VERSION ""

NS_ :

BS_:

BU_: VCU BMS Dash Daq RMS_PM_Controller

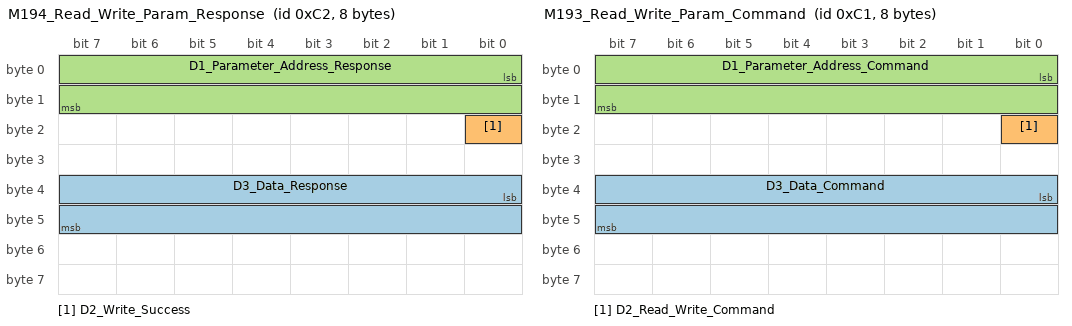
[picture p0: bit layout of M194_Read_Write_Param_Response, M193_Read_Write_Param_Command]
BO_ 194 M194_Read_Write_Param_Response: 8 RMS_PM_Controller
 SG_ D3_Data_Response : 32|16@1- (1,0) [-32768|32767] "" Vector__XXX
 SG_ D2_Write_Success : 16|1@1+ (1,0) [0|1] "" Vector__XXX
 SG_ D1_Parameter_Address_Response : 0|16@1+ (1,0) [0|65535] "" Vector__XXX

BO_ 193 M193_Read_Write_Param_Command: 8 RMS_PM_Controller
 SG_ D3_Data_Command : 32|16@1- (1,0) [-32768|32767] "" Vector__XXX
 SG_ D2_Read_Write_Command : 16|1@1+ (1,0) [0|1] "" Vector__XXX
 SG_ D1_Parameter_Address_Command : 0|16@1+ (1,0) [0|65535] "" Vector__XXX

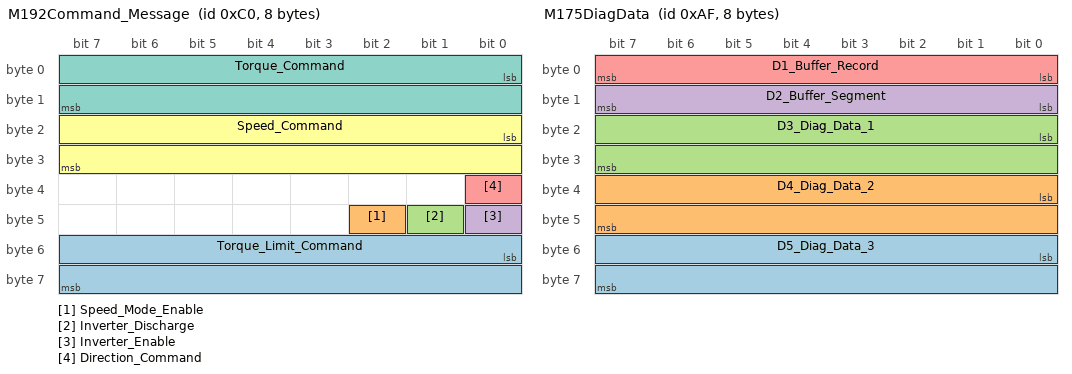
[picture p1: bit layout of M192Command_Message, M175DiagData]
BO_ 192 M192Command_Message: 8 RMS_PM_Controller
 SG_ Torque_Limit_Command : 48|16@1- (0.1,0) [-3276.8|3276.7] "" Vector__XXX
 SG_ Speed_Mode_Enable : 42|1@1+ (1,0) [0|1] "" Vector__XXX
 SG_ Inverter_Discharge : 41|1@1+ (1,0) [0|1] "" Vector__XXX
 SG_ Inverter_Enable : 40|1@1+ (1,0) [0|1] "" Vector__XXX
 SG_ Direction_Command : 32|1@1+ (1,0) [0|1] "" Vector__XXX
 SG_ Speed_Command : 16|16@1- (1,0) [-32768|32767] "" Vector__XXX
 SG_ Torque_Command : 0|16@1- (0.1,0) [-3276.8|3276.7] "" Vector__XXX

BO_ 175 M175DiagData: 8 RMS_PM_Controller
 SG_ D5_Diag_Data_3 : 48|16@1- (1,0) [-32768|32767] "" Vector__XXX
 SG_ D4_Diag_Data_2 : 32|16@1- (1,0) [-32768|32767] "" Vector__XXX
 SG_ D3_Diag_Data_1 : 16|16@1- (1,0) [-32768|32767] "" Vector__XXX
 SG_ D2_Buffer_Segment : 8|8@1+ (1,0) [0|5] "" Vector__XXX
 SG_ D1_Buffer_Record : 0|8@1+ (1,0) [0|255] "" Vector__XXX

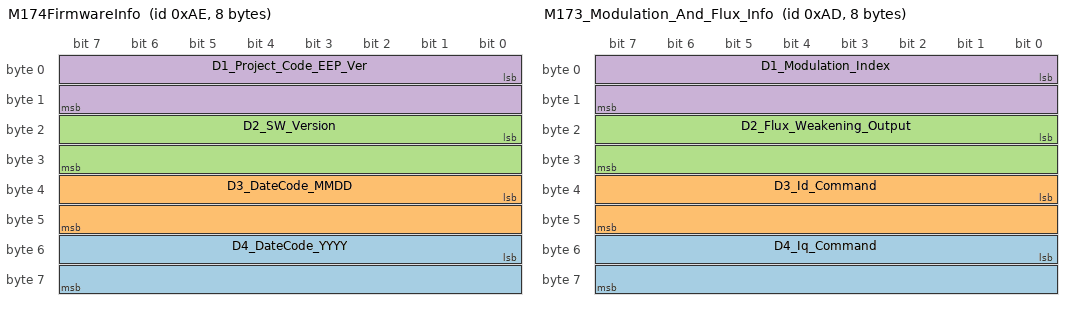
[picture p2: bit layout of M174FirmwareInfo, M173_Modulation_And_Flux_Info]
BO_ 174 M174FirmwareInfo: 8 RMS_PM_Controller
 SG_ D4_DateCode_YYYY : 48|16@1+ (1,0) [0|65535] "" Vector__XXX
 SG_ D3_DateCode_MMDD : 32|16@1+ (1,0) [0|65535] "" Vector__XXX
 SG_ D2_SW_Version : 16|16@1+ (1,0) [0|65535] "" Vector__XXX
 SG_ D1_Project_Code_EEP_Ver : 0|16@1+ (1,0) [0|65535] "" Vector__XXX

BO_ 173 M173_Modulation_And_Flux_Info: 8 RMS_PM_Controller
 SG_ D4_Iq_Command : 48|16@1- (0.1,0) [-3276.8|3276.7] "" Vector__XXX
 SG_ D3_Id_Command : 32|16@1- (0.1,0) [-3276.8|3276.7] "" Vector__XXX
 SG_ D2_Flux_Weakening_Output : 16|16@1- (0.1,0) [-3276.8|3276.7] "" Vector__XXX
 SG_ D1_Modulation_Index : 0|16@1- (0.0001,0) [-3.2768|3.2767] "" Vector__XXX

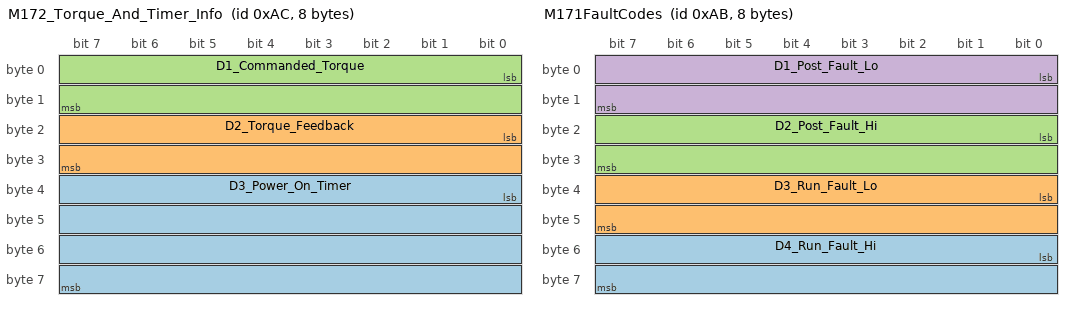
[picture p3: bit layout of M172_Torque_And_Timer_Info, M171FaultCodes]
BO_ 172 M172_Torque_And_Timer_Info: 8 RMS_PM_Controller
 SG_ D3_Power_On_Timer : 32|32@1+ (0.003,0) [0|12884800.0] "" Vector__XXX
 SG_ D2_Torque_Feedback : 16|16@1- (0.1,0) [-3276.8|3276.7] "" Vector__XXX
 SG_ D1_Commanded_Torque : 0|16@1- (0.1,0) [-3276.8|3276.7] "" Vector__XXX

BO_ 171 M171FaultCodes: 8 RMS_PM_Controller
 SG_ D4_Run_Fault_Hi : 48|16@1+ (1,0) [0|65535] "" Vector__XXX
 SG_ D3_Run_Fault_Lo : 32|16@1+ (1,0) [0|65535] "" Vector__XXX
 SG_ D2_Post_Fault_Hi : 16|16@1+ (1,0) [0|65535] "" Vector__XXX
 SG_ D1_Post_Fault_Lo : 0|16@1+ (1,0) [0|65535] "" Vector__XXX

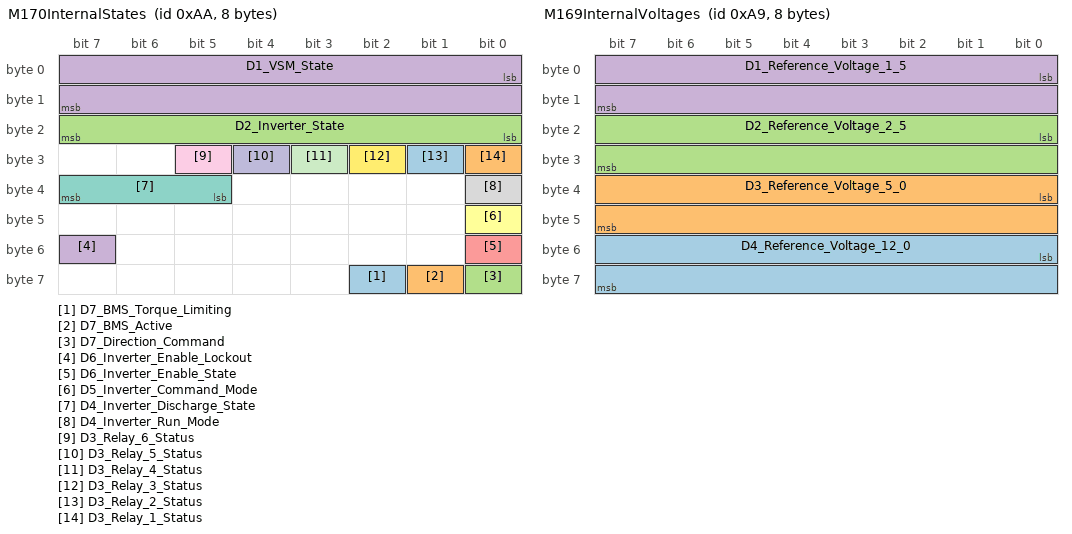
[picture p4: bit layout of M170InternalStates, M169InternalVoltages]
BO_ 170 M170InternalStates: 8 RMS_PM_Controller
 SG_ D7_BMS_Torque_Limiting : 58|1@1+ (1,0) [0|0] "" Vector__XXX
 SG_ D7_BMS_Active : 57|1@1+ (1,0) [0|1] "" Vector__XXX
 SG_ D7_Direction_Command : 56|1@1+ (1,0) [0|1] "" Vector__XXX
 SG_ D6_Inverter_Enable_Lockout : 55|1@1+ (1,0) [0|1] "" Vector__XXX
 SG_ D6_Inverter_Enable_State : 48|1@1+ (1,0) [0|1] "" Vector__XXX
 SG_ D5_Inverter_Command_Mode : 40|1@1+ (1,0) [0|1] "" Vector__XXX
 SG_ D4_Inverter_Discharge_State : 37|3@1+ (1,0) [0|7] "" Vector__XXX
 SG_ D4_Inverter_Run_Mode : 32|1@1+ (1,0) [0|1] "" Vector__XXX
 SG_ D3_Relay_6_Status : 29|1@1+ (1,0) [0|1] "" Vector__XXX
 SG_ D3_Relay_5_Status : 28|1@1+ (1,0) [0|1] "" Vector__XXX
 SG_ D3_Relay_4_Status : 27|1@1+ (1,0) [0|1] "" Vector__XXX
 SG_ D3_Relay_3_Status : 26|1@1+ (1,0) [0|1] "" Vector__XXX
 SG_ D3_Relay_2_Status : 25|1@1+ (1,0) [0|1] "" Vector__XXX
 SG_ D3_Relay_1_Status : 24|1@1+ (1,0) [0|1] "" Vector__XXX
 SG_ D2_Inverter_State : 16|8@1+ (1,0) [0|255] "" Vector__XXX
 SG_ D1_VSM_State : 0|16@1+ (1,0) [0|15] "" Vector__XXX

BO_ 169 M169InternalVoltages: 8 RMS_PM_Controller
 SG_ D4_Reference_Voltage_12_0 : 48|16@1- (0.01,0) [-327.68|327.67] "" Vector__XXX
 SG_ D3_Reference_Voltage_5_0 : 32|16@1- (0.01,0) [-327.68|327.67] "" Vector__XXX
 SG_ D2_Reference_Voltage_2_5 : 16|16@1- (0.01,0) [-327.68|327.67] "" Vector__XXX
 SG_ D1_Reference_Voltage_1_5 : 0|16@1- (0.01,0) [-327.68|327.67] "" Vector__XXX

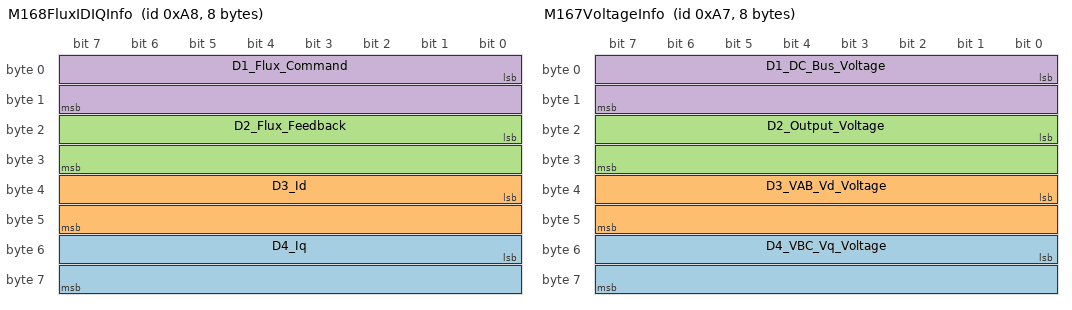
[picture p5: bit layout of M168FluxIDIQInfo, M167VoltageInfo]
BO_ 168 M168FluxIDIQInfo: 8 RMS_PM_Controller
 SG_ D4_Iq : 48|16@1- (0.1,0) [-3276.8|3276.7] "" Vector__XXX
 SG_ D3_Id : 32|16@1- (0.1,0) [-3276.8|3276.7] "" Vector__XXX
 SG_ D2_Flux_Feedback : 16|16@1- (0.001,0) [-32.768|32.767] "" Vector__XXX
 SG_ D1_Flux_Command : 0|16@1- (0.001,0) [-32.768|32.767] "" Vector__XXX

BO_ 167 M167VoltageInfo: 8 RMS_PM_Controller
 SG_ D4_VBC_Vq_Voltage : 48|16@1- (0.1,0) [-3276.8|3276.7] "" Vector__XXX
 SG_ D3_VAB_Vd_Voltage : 32|16@1- (0.1,0) [-3276.8|3276.7] "" Vector__XXX
 SG_ D2_Output_Voltage : 16|16@1- (0.1,0) [-3276.8|3276.7] "" Vector__XXX
 SG_ D1_DC_Bus_Voltage : 0|16@1- (0.1,0) [-3276.8|3276.7] "" Vector__XXX

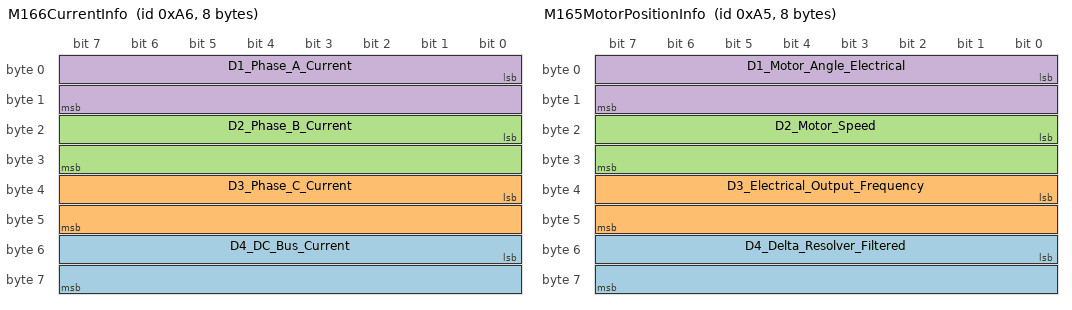
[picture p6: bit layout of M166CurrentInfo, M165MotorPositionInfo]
BO_ 166 M166CurrentInfo: 8 RMS_PM_Controller
 SG_ D4_DC_Bus_Current : 48|16@1- (0.1,0) [-3276.8|3276.7] "" Vector__XXX
 SG_ D3_Phase_C_Current : 32|16@1- (0.1,0) [-3276.8|3276.7] "" Vector__XXX
 SG_ D2_Phase_B_Current : 16|16@1- (0.1,0) [-3276.8|3276.7] "" Vector__XXX
 SG_ D1_Phase_A_Current : 0|16@1- (0.1,0) [-3276.8|3276.7] "" Vector__XXX

BO_ 165 M165MotorPositionInfo: 8 RMS_PM_Controller
 SG_ D4_Delta_Resolver_Filtered : 48|16@1- (0.1,0) [-3276.8|3276.7] "" Vector__XXX
 SG_ D3_Electrical_Output_Frequency : 32|16@1- (0.1,0) [-3276.8|3276.7] "" Vector__XXX
 SG_ D2_Motor_Speed : 16|16@1- (1,0) [-32768|32767] "" Vector__XXX
 SG_ D1_Motor_Angle_Electrical : 0|16@1+ (0.1,0) [0|6553.5] "" Vector__XXX

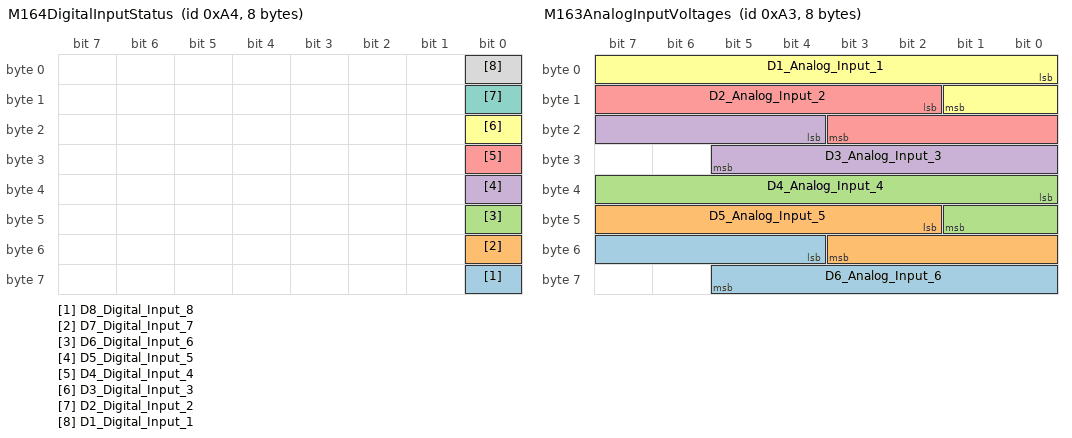
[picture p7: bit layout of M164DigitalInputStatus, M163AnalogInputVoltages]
BO_ 164 M164DigitalInputStatus: 8 RMS_PM_Controller
 SG_ D8_Digital_Input_8 : 56|1@1+ (1,0) [0|1] "" Vector__XXX
 SG_ D7_Digital_Input_7 : 48|1@1+ (1,0) [0|1] "" Vector__XXX
 SG_ D6_Digital_Input_6 : 40|1@1+ (1,0) [0|1] "" Vector__XXX
 SG_ D5_Digital_Input_5 : 32|1@1+ (1,0) [0|1] "" Vector__XXX
 SG_ D4_Digital_Input_4 : 24|1@1+ (1,0) [0|1] "" Vector__XXX
 SG_ D3_Digital_Input_3 : 16|1@1+ (1,0) [0|1] "" Vector__XXX
 SG_ D2_Digital_Input_2 : 8|1@1+ (1,0) [0|1] "" Vector__XXX
 SG_ D1_Digital_Input_1 : 0|1@1+ (1,0) [0|1] "" Vector__XXX

BO_ 163 M163AnalogInputVoltages: 8 RMS_PM_Controller
 SG_ D6_Analog_Input_6 : 52|10@1+ (0.01,0) [0|10.23] "" Vector__XXX
 SG_ D5_Analog_Input_5 : 42|10@1+ (0.01,0) [0|10.23] "" Vector__XXX
 SG_ D4_Analog_Input_4 : 32|10@1+ (0.01,0) [0|10.23] "" Vector__XXX
 SG_ D3_Analog_Input_3 : 20|10@1+ (0.01,0) [0|10.23] "" Vector__XXX
 SG_ D2_Analog_Input_2 : 10|10@1+ (0.01,0) [0|10.23] "" Vector__XXX
 SG_ D1_Analog_Input_1 : 0|10@1+ (0.01,0) [0|10.23] "" Vector__XXX

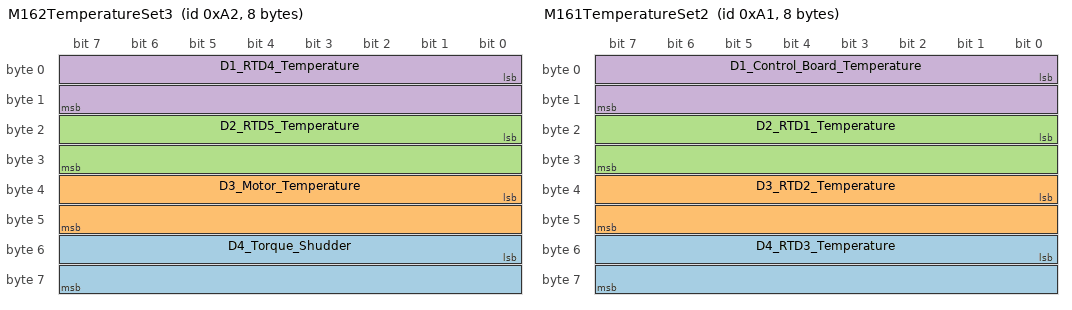
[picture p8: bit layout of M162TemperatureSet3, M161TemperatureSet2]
BO_ 162 M162TemperatureSet3: 8 RMS_PM_Controller
 SG_ D4_Torque_Shudder : 48|16@1- (0.1,0) [-3276.8|3276.7] "" Vector__XXX
 SG_ D3_Motor_Temperature : 32|16@1- (0.1,0) [-3276.8|3276.7] "" Vector__XXX
 SG_ D2_RTD5_Temperature : 16|16@1- (0.1,0) [-3276.8|3276.7] "" Vector__XXX
 SG_ D1_RTD4_Temperature : 0|16@1- (0.1,0) [-3276.8|3276.7] "" Vector__XXX

BO_ 161 M161TemperatureSet2: 8 RMS_PM_Controller
 SG_ D4_RTD3_Temperature : 48|16@1- (0.1,0) [-3276.8|3276.7] "" Vector__XXX
 SG_ D3_RTD2_Temperature : 32|16@1- (0.1,0) [-3276.8|3276.7] "" Vector__XXX
 SG_ D2_RTD1_Temperature : 16|16@1- (0.1,0) [-3276.8|3276.7] "" Vector__XXX
 SG_ D1_Control_Board_Temperature : 0|16@1- (0.1,0) [-3276.8|3276.7] "" Vector__XXX

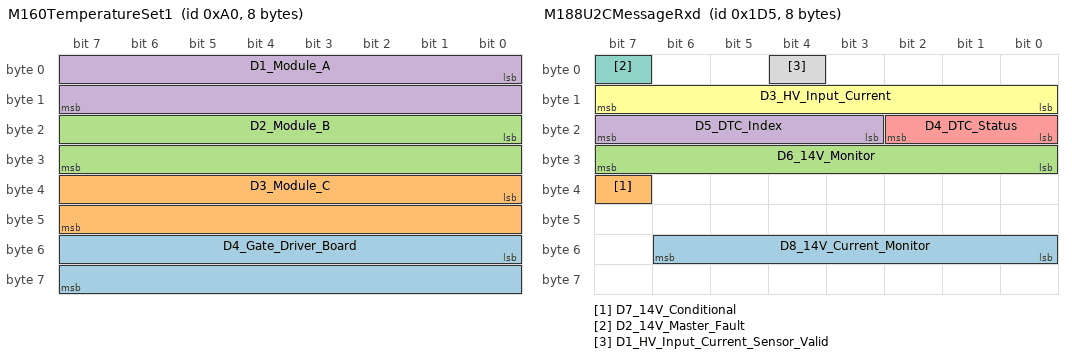
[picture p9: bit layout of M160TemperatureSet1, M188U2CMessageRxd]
BO_ 160 M160TemperatureSet1: 8 RMS_PM_Controller
 SG_ D4_Gate_Driver_Board : 48|16@1- (0.1,0) [-3276.8|3276.7] "" Vector__XXX
 SG_ D3_Module_C : 32|16@1- (0.1,0) [-3276.8|3276.7] "" Vector__XXX
 SG_ D2_Module_B : 16|16@1- (0.1,0) [-3276.8|3276.7] "" Vector__XXX
 SG_ D1_Module_A : 0|16@1- (0.1,0) [-3276.8|3276.7] "" Vector__XXX

BO_ 471 M187U2CCommandTxd: 8 RMS_PM_Controller
 SG_ D2_Setpoint_Calc : 8|8@1+ (1,0) [0|255] "" Vector__XXX
 SG_ D1_ID_Byte : 0|8@1+ (1,0) [0|255] "" Vector__XXX

BO_ 469 M188U2CMessageRxd: 8 RMS_PM_Controller
 SG_ D8_14V_Current_Monitor : 48|7@1+ (1,0) [0|127] "" Vector__XXX
 SG_ D7_14V_Conditional : 39|1@1+ (1,0) [0|1] "" Vector__XXX
 SG_ D6_14V_Monitor : 24|8@1+ (1,0) [0|255] "" Vector__XXX
 SG_ D5_DTC_Index : 19|5@1+ (1,0) [0|31] "" Vector__XXX
 SG_ D4_DTC_Status : 16|3@1+ (1,0) [0|7] "" Vector__XXX
 SG_ D3_HV_Input_Current : 8|8@1+ (1,0) [0|255] "" Vector__XXX
 SG_ D2_14V_Master_Fault : 7|1@1+ (1,0) [0|1] "" Vector__XXX
 SG_ D1_HV_Input_Current_Sensor_Valid : 4|1@1+ (1,0) [0|1] "" Vector__XXX

BO_ 200 VcuFirmwareVersion: 4 VCU
 SG_ fw_version : 0|32@1+ (1,0) [0|0] "" Vector__XXX

BO_ 198 VcuWheelspeedReadings: 8 VCU
 SG_ RPM_FR : 32|32@1+ (0.01,0) [0|4294967296] "" Vector__XXX
 SG_ RPM_FL : 0|32@1+ (0.01,0) [0|4294967296] "" Vector__XXX

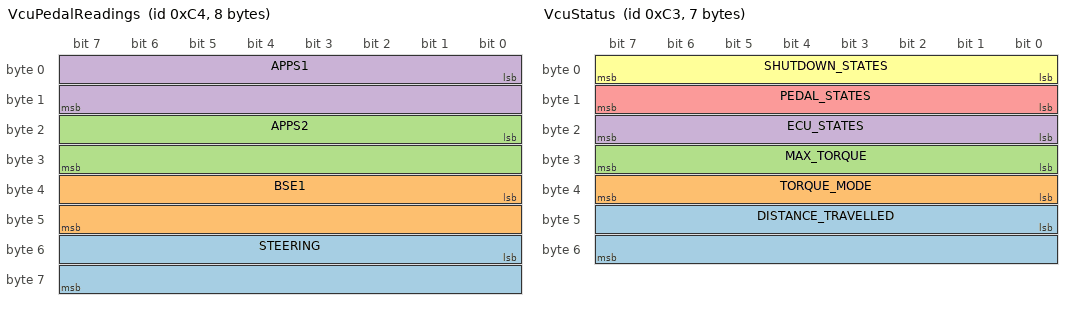
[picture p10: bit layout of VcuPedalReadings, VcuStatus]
BO_ 196 VcuPedalReadings: 8 VCU
 SG_ STEERING : 48|16@1+ (0.001220703125,0) [0|12] "" Vector__XXX
 SG_ BSE1 : 32|16@1+ (0.001220703125,0) [0|12] "" Vector__XXX
 SG_ APPS2 : 16|16@1+ (0.001220703125,0) [0|12] "" Vector__XXX
 SG_ APPS1 : 0|16@1+ (0.001220703125,0) [0|12] "" Vector__XXX

BO_ 195 VcuStatus: 7 VCU
 SG_ DISTANCE_TRAVELLED : 40|16@1+ (1,0) [0|65535] "" Vector__XXX
 SG_ TORQUE_MODE : 32|8@1+ (1,0) [0|255] "" Vector__XXX
 SG_ MAX_TORQUE : 24|8@1+ (1,0) [0|255] "" Vector__XXX
 SG_ ECU_STATES : 16|8@1+ (1,0) [0|255] "" Vector__XXX
 SG_ PEDAL_STATES : 8|8@1+ (1,0) [0|255] "" Vector__XXX
 SG_ SHUTDOWN_STATES : 0|8@1+ (1,0) [0|255] "" Vector__XXX

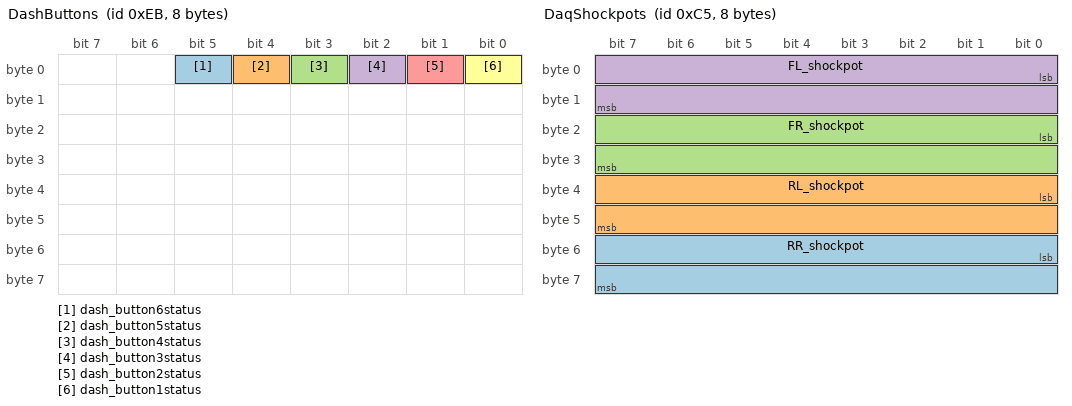
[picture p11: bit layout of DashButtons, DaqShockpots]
BO_ 235 DashButtons: 8 Dash
 SG_ dash_button6status : 5|1@1+ (1,0) [0|0] "" Vector__XXX
 SG_ dash_button5status : 4|1@1+ (1,0) [0|0] "" Vector__XXX
 SG_ dash_button4status : 3|1@1+ (1,0) [0|0] "" Vector__XXX
 SG_ dash_button3status : 2|1@1+ (1,0) [0|0] "" Vector__XXX
 SG_ dash_button2status : 1|1@1+ (1,0) [0|0] "" Vector__XXX
 SG_ dash_button1status : 0|1@1+ (1,0) [0|0] "" Vector__XXX

BO_ 197 DaqShockpots: 8 Daq
 SG_ RR_shockpot : 48|16@1+ (1,0) [0|65535] "" Vector__XXX
 SG_ RL_shockpot : 32|16@1+ (1,0) [0|65535] "" Vector__XXX
 SG_ FR_shockpot : 16|16@1+ (1,0) [0|65535] "" Vector__XXX
 SG_ FL_shockpot : 0|16@1+ (1,0) [0|65535] "" Vector__XXX

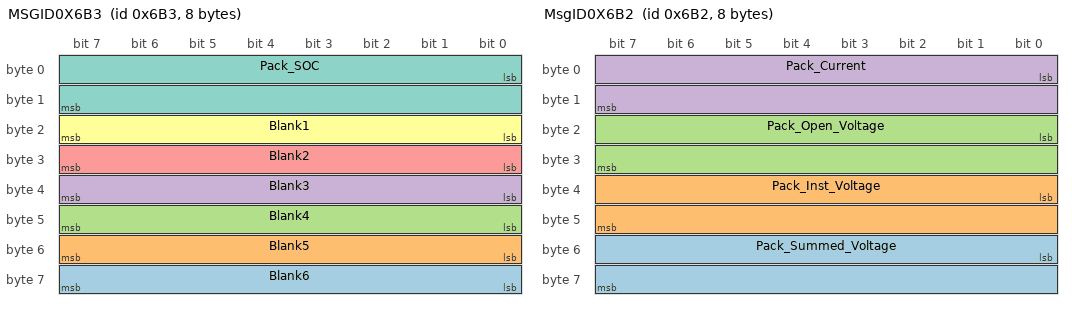
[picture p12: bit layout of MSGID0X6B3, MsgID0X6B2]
BO_ 1715 MSGID0X6B3: 8 BMS
 SG_ Blank6 : 63|8@0+ (1,0) [0|0] "" Vector__XXX
 SG_ Blank5 : 55|8@0+ (1,0) [0|0] "" Vector__XXX
 SG_ Blank4 : 47|8@0+ (1,0) [0|0] "" Vector__XXX
 SG_ Blank3 : 39|8@0+ (1,0) [0|0] "" Vector__XXX
 SG_ Blank2 : 31|8@0+ (1,0) [0|0] "" Vector__XXX
 SG_ Blank1 : 23|8@0+ (1,0) [0|0] "" Vector__XXX
 SG_ Pack_SOC : 0|16@1+ (0.5,0) [0|0] "" Vector__XXX

BO_ 1714 MsgID0X6B2: 8 BMS
 SG_ Pack_Summed_Voltage : 48|16@1+ (0.01,0) [0|0] "" Vector__XXX
 SG_ Pack_Inst_Voltage : 32|16@1+ (0.1,0) [0|0] "" Vector__XXX
 SG_ Pack_Open_Voltage : 16|16@1+ (0.1,0) [0|0] "" Vector__XXX
 SG_ Pack_Current : 0|16@1- (0.1,0) [0|0] "" Vector__XXX

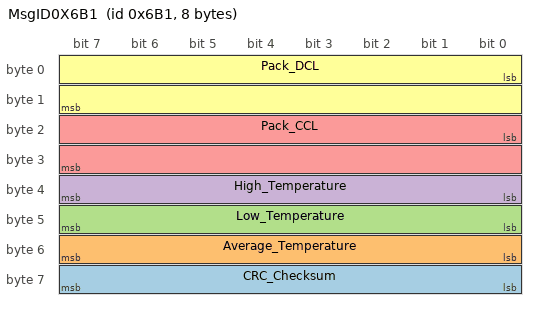
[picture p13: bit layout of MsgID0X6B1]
BO_ 1713 MsgID0X6B1: 8 BMS
 SG_ CRC_Checksum : 63|8@0+ (1,0) [0|0] "" Vector__XXX
 SG_ Average_Temperature : 55|8@0+ (1,0) [0|0] "" Vector__XXX
 SG_ Low_Temperature : 47|8@0+ (1,0) [0|0] "" Vector__XXX
 SG_ High_Temperature : 39|8@0+ (1,0) [0|0] "" Vector__XXX
 SG_ Pack_CCL : 16|16@1+ (1,0) [0|0] "" Vector__XXX
 SG_ Pack_DCL : 0|16@1+ (1,0) [0|0] "" Vector__XXX

BO_ 514 BmsCurrentLimit: 8 BMS
 SG_ D2_Max_Charge_Current : 16|16@1+ (1,0) [0|1000] "" Vector__XXX
 SG_ D1_Max_Discharge_Current : 0|16@1+ (1,0) [0|1000] "" Vector__XXX

BO_ 41 Segment1Temps1: 10 Vector__XXX
 SG_ maxtemp1to6 : 56|8@1+ (0.019607,0) [0.0|5.0] "" Vector__XXX
 SG_ mintemp1to6 : 48|8@1+ (0.019607,0) [0.0|5.0] "" Vector__XXX
 SG_ cell6temp : 40|8@1+ (0.019607,0) [0.0|5.0] "" Vector__XXX
 SG_ cell5temp : 32|8@1+ (0.019607,0) [0.0|5.0] "" Vector__XXX
 SG_ cell4temp : 24|8@1+ (0.019607,0) [0.0|5.0] "" Vector__XXX
 SG_ cell3temp : 16|8@1+ (0.019607,0) [0.0|5.0] "" Vector__XXX
 SG_ cell2temp : 8|8@1+ (0.019607,0) [0.0|5.0] "" Vector__XXX
 SG_ cell1temp : 0|8@1+ (0.019607,0) [0.0|5.0] "" Vector__XXX

BO_ 40 Segment1Temps2: 11 Vector__XXX
 SG_ maxtemp7to12 : 56|8@1+ (0.019607,0) [0.0|5.0] "" Vector__XXX
 SG_ mintemp7to12 : 48|8@1+ (0.019607,0) [0.0|5.0] "" Vector__XXX
 SG_ cell12temp : 40|8@1+ (0.019607,0) [0.0|5.0] "" Vector__XXX
 SG_ cell11temp : 32|8@1+ (0.019607,0) [0.0|5.0] "" Vector__XXX
 SG_ cell10temp : 24|8@1+ (0.019607,0) [0.0|5.0] "" Vector__XXX
 SG_ cell9temp : 16|8@1+ (0.019607,0) [0.0|5.0] "" Vector__XXX
 SG_ cell8temp : 8|8@1+ (0.019607,0) [0.0|5.0] "" Vector__XXX
 SG_ cell7temp : 0|8@1+ (0.019607,0) [0.0|5.0] "" Vector__XXX

BO_ 39 Segment2temps1: 12 Vector__XXX
 SG_ maxtemp13to18 : 56|8@1+ (0.019607,0) [0.0|5.0] "" Vector__XXX
 SG_ mintemp13to18 : 48|8@1+ (0.019607,0) [0.0|5.0] "" Vector__XXX
 SG_ cell18temp : 40|8@1+ (0.019607,0) [0.0|5.0] "" Vector__XXX
 SG_ cell17temp : 32|8@1+ (0.019607,0) [0.0|5.0] "" Vector__XXX
 SG_ cell16temp : 24|8@1+ (0.019607,0) [0.0|5.0] "" Vector__XXX
 SG_ cell15temp : 16|8@1+ (0.019607,0) [0.0|5.0] "" Vector__XXX
 SG_ cell14temp : 8|8@1+ (0.019607,0) [0.0|5.0] "" Vector__XXX
 SG_ cell13temp : 0|8@1+ (0.019607,0) [0.0|5.0] "" Vector__XXX

BO_ 38 Segmet2Temps2: 13 Vector__XXX
 SG_ maxtemp19to24 : 56|8@1+ (0.019607,0) [0.0|5.0] "" Vector__XXX
 SG_ mintemp19to24 : 48|8@1+ (0.019607,0) [0.0|5.0] "" Vector__XXX
 SG_ cell24temp : 40|8@1+ (0.019607,0) [0.0|5.0] "" Vector__XXX
 SG_ cell23temp : 32|8@1+ (0.019607,0) [0.0|5.0] "" Vector__XXX
 SG_ cell22temp : 24|8@1+ (0.019607,0) [0.0|5.0] "" Vector__XXX
 SG_ cell21temp : 16|8@1+ (0.019607,0) [0.0|5.0] "" Vector__XXX
 SG_ cell20temp : 8|8@1+ (0.019607,0) [0.0|5.0] "" Vector__XXX
 SG_ cell19temp : 0|8@1+ (0.019607,0) [0.0|5.0] "" Vector__XXX

BO_ 37 Segment3Temps1: 14 Vector__XXX
 SG_ maxtemp25to30 : 56|8@1+ (0.019607,0) [0.0|5.0] "" Vector__XXX
 SG_ mintemp25to30 : 48|8@1+ (0.019607,0) [0.0|5.0] "" Vector__XXX
 SG_ cell30temp : 40|8@1+ (0.019607,0) [0.0|5.0] "" Vector__XXX
 SG_ cell29temp : 32|8@1+ (0.019607,0) [0.0|5.0] "" Vector__XXX
 SG_ cell28temp : 24|8@1+ (0.019607,0) [0.0|5.0] "" Vector__XXX
 SG_ cell27temp : 16|8@1+ (0.019607,0) [0.0|5.0] "" Vector__XXX
 SG_ cell26temp : 8|8@1+ (0.019607,0) [0.0|5.0] "" Vector__XXX
 SG_ cell25temp : 0|8@1+ (0.019607,0) [0.0|5.0] "" Vector__XXX

BO_ 36 Segment3Temps2: 15 Vector__XXX
 SG_ maxtemp31to36 : 56|8@1+ (0.019607,0) [0.0|5.0] "" Vector__XXX
 SG_ mintemp31to36 : 48|8@1+ (0.019607,0) [0.0|5.0] "" Vector__XXX
 SG_ cell36temp : 40|8@1+ (0.019607,0) [0.0|5.0] "" Vector__XXX
 SG_ cell35temp : 32|8@1+ (0.019607,0) [0.0|5.0] "" Vector__XXX
 SG_ cell34temp : 24|8@1+ (0.019607,0) [0.0|5.0] "" Vector__XXX
 SG_ cell33temp : 16|8@1+ (0.019607,0) [0.0|5.0] "" Vector__XXX
 SG_ cell32temp : 8|8@1+ (0.019607,0) [0.0|5.0] "" Vector__XXX
 SG_ cell31temp : 0|8@1+ (0.019607,0) [0.0|5.0] "" Vector__XXX

BO_ 35 Segment4Temps1: 16 Vector__XXX
 SG_ maxtemp37to42 : 56|8@1+ (0.019607,0) [0.0|5.0] "" Vector__XXX
 SG_ mintemp37to42 : 48|8@1+ (0.019607,0) [0.0|5.0] "" Vector__XXX
 SG_ cell42temp : 40|8@1+ (0.019607,0) [0.0|5.0] "" Vector__XXX
 SG_ cell41temp : 32|8@1+ (0.019607,0) [0.0|5.0] "" Vector__XXX
 SG_ cell40temp : 24|8@1+ (0.019607,0) [0.0|5.0] "" Vector__XXX
 SG_ cell39temp : 16|8@1+ (0.019607,0) [0.0|5.0] "" Vector__XXX
 SG_ cell38temp : 8|8@1+ (0.019607,0) [0.0|5.0] "" Vector__XXX
 SG_ cell37temp : 0|8@1+ (0.019607,0) [0.0|5.0] "" Vector__XXX

BO_ 34 Segment4Temps2: 17 Vector__XXX
 SG_ maxtemp43to48 : 56|8@1+ (0.019607,0) [0.0|5.0] "" Vector__XXX
 SG_ mintemp43to48 : 48|8@1+ (0.019607,0) [0.0|5.0] "" Vector__XXX
 SG_ cell48temp : 40|8@1+ (0.019607,0) [0.0|5.0] "" Vector__XXX
 SG_ cell47temp : 32|8@1+ (0.019607,0) [0.0|5.0] "" Vector__XXX
 SG_ cell46temp : 24|8@1+ (0.019607,0) [0.0|5.0] "" Vector__XXX
 SG_ cell45temp : 16|8@1+ (0.019607,0) [0.0|5.0] "" Vector__XXX
 SG_ cell44temp : 8|8@1+ (0.019607,0) [0.0|5.0] "" Vector__XXX
 SG_ cell43temp : 0|8@1+ (0.019607,0) [0.0|5.0] "" Vector__XXX

BO_ 33 Segment5Temps1: 18 Vector__XXX
 SG_ maxtemp49to54 : 56|8@1+ (0.019607,0) [0.0|5.0] "" Vector__XXX
 SG_ mintemp49to54 : 48|8@1+ (0.019607,0) [0.0|5.0] "" Vector__XXX
 SG_ cell54temp : 40|8@1+ (0.019607,0) [0.0|5.0] "" Vector__XXX
 SG_ cell53temp : 32|8@1+ (0.019607,0) [0.0|5.0] "" Vector__XXX
 SG_ cell52temp : 24|8@1+ (0.019607,0) [0.0|5.0] "" Vector__XXX
 SG_ cell51temp : 16|8@1+ (0.019607,0) [0.0|5.0] "" Vector__XXX
 SG_ cell50temp : 8|8@1+ (0.019607,0) [0.0|5.0] "" Vector__XXX
 SG_ cell49temp : 0|8@1+ (0.019607,0) [0.0|5.0] "" Vector__XXX

BO_ 32 Segment5Temps2: 19 Vector__XXX
 SG_ maxtemp55to60 : 56|8@1+ (0.019607,0) [0.0|5.0] "" Vector__XXX
 SG_ mintemp55to60 : 48|8@1+ (0.019607,0) [0.0|5.0] "" Vector__XXX
 SG_ cell60temp : 40|8@1+ (0.019607,0) [0.0|5.0] "" Vector__XXX
 SG_ cell59temp : 32|8@1+ (0.019607,0) [0.0|5.0] "" Vector__XXX
 SG_ cell58temp : 24|8@1+ (0.019607,0) [0.0|5.0] "" Vector__XXX
 SG_ cell57temp : 16|8@1+ (0.019607,0) [0.0|5.0] "" Vector__XXX
 SG_ cell56temp : 8|8@1+ (0.019607,0) [0.0|5.0] "" Vector__XXX
 SG_ cell55temp : 0|8@1+ (0.019607,0) [0.0|5.0] "" Vector__XXX

BO_ 31 Segment6Temps1: 20 Vector__XXX
 SG_ maxtemp61to66 : 56|8@1+ (0.019607,0) [0.0|5.0] "" Vector__XXX
 SG_ mintemp61to66 : 48|8@1+ (0.019607,0) [0.0|5.0] "" Vector__XXX
 SG_ cell66temp : 40|8@1+ (0.019607,0) [0.0|5.0] "" Vector__XXX
 SG_ cell65temp : 32|8@1+ (0.019607,0) [0.0|5.0] "" Vector__XXX
 SG_ cell64temp : 24|8@1+ (0.019607,0) [0.0|5.0] "" Vector__XXX
 SG_ cell63temp : 16|8@1+ (0.019607,0) [0.0|5.0] "" Vector__XXX
 SG_ cell62temp : 8|8@1+ (0.019607,0) [0.0|5.0] "" Vector__XXX
 SG_ cell61temp : 0|8@1+ (0.019607,0) [0.0|5.0] "" Vector__XXX

BO_ 30 Segment6Temps2: 21 Vector__XXX
 SG_ maxtemp67to72 : 56|8@1+ (0.019607,0) [0.0|5.0] "" Vector__XXX
 SG_ mintemp67to72 : 48|8@1+ (0.019607,0) [0.0|5.0] "" Vector__XXX
 SG_ cell72temp : 40|8@1+ (0.019607,0) [0.0|5.0] "" Vector__XXX
 SG_ cell71temp : 32|8@1+ (0.019607,0) [0.0|5.0] "" Vector__XXX
 SG_ cell70temp : 24|8@1+ (0.019607,0) [0.0|5.0] "" Vector__XXX
 SG_ cell69temp : 16|8@1+ (0.019607,0) [0.0|5.0] "" Vector__XXX
 SG_ cell68temp : 8|8@1+ (0.019607,0) [0.0|5.0] "" Vector__XXX
 SG_ cell67temp : 0|8@1+ (0.019607,0) [0.0|5.0] "" Vector__XXX

CM_ BU_ vcu "the vehicle control unit";
CM_ BO_ 194 "To write a parameter use message 0x0C1 with byte #2 set to 1 (write). 
To read a parameter use message 0x0C1 with byte #2 to set 0 (read). ";
CM_ BO_ 193 "To write a parameter use message 0x0C1 with byte #2 set to 1 (write). 
To read a parameter use message 0x0C1 with byte #2 to set 0 (read). ";
CM_ BO_ 192 "The command message is used to transmit data to the controller. This message is sent from a user supplied external controller to the PMxxx controller.";

CM_ BO_ 514 "Sent by BMS";
 CM_ SG_ 514 "D2 max charge current"
 CM_ SG_ 514 "D1 max discharge current"

CM_ BO_ 196 "VCU analog pedal readings";
 CM_ SG_ 196 "STEERING"
 CM_ SG_ 196 "BSE1"
 CM_ SG_ 196 "APPS2"
 CM_ SG_ 196 "APPS1"

CM_ BO_ 198 "VCU wheel speed sensor readings";
 CM_ SG_ 198 "RPM FR";
 CM_ SG_ 198 "RPM FL";

CM_ BO_ 197 "DAQ node shonk pot readings";
CM_ BO_ 200 "commit hash of the firmware on the VCU";
CM_ BO_ 235 "commit hash of the firmware on the VCU";
CM_ BO_ 1713 "This ID Transmits at 104 ms.";
CM_ BO_ 1714 "This ID Transmits at 48 ms.";
CM_ BO_ 1715 "This ID Transmits at 1008 ms.";

CM_ BO_ 26 "raw ADC voltage reading of module1 cells 1-6";
 CM_ SG_ 26 "maximum cell temp from 1 to 6";
 CM_ SG_ 26 "minimum cell temp from 1 to 6";
 CM_ SG_ 26 "cell 6 temp";
 CM_ SG_ 26 "cell 5 temp";
 CM_ SG_ 26 "cell 4 temp";
 CM_ SG_ 26 "cell 3 temp";
 CM_ SG_ 26 "cell 2 temp";
 CM_ SG_ 26 "cell 1 temp";

CM_ BO_ 27 "raw ADC voltage reading of module1 cells 7-12";
 CM_ SG_ 27 "maximum cell temp from 7 to 12";
 CM_ SG_ 27 "minimum cell temp from 7 to 12";
 CM_ SG_ 27 "cell 12 temp";
 CM_ SG_ 27 "cell 11 temp";
 CM_ SG_ 27 "cell 10 temp";
 CM_ SG_ 27 "cell 9 temp";
 CM_ SG_ 27 "cell 8 temp";
 CM_ SG_ 27 "cell 7 temp";

CM_ BO_ 42 "raw ADC voltage reading of module2 cells 1-6";
 CM_ SG_ 42 "maximum cell temp from 13 to 18";
 CM_ SG_ 42 "minimum cell temp from 13 to 18";
 CM_ SG_ 42 "cell 18 temp";
 CM_ SG_ 42 "cell 17 temp";
 CM_ SG_ 42 "cell 16 temp";
 CM_ SG_ 42 "cell 15 temp";
 CM_ SG_ 42 "cell 14 temp";
 CM_ SG_ 42 "cell 13 temp";

CM_ BO_ 43 "raw ADC voltage reading of module2 cells 7-12";
 CM_ SG_ 43 "maximum cell temp from 19 to 24";
 CM_ SG_ 43 "minimum cell temp from 19 to 24";
 CM_ SG_ 43 "cell 24 temp";
 CM_ SG_ 43 "cell 23 temp";
 CM_ SG_ 43 "cell 22 temp";
 CM_ SG_ 43 "cell 21 temp";
 CM_ SG_ 43 "cell 20 temp";
 CM_ SG_ 43 "cell 19 temp";

CM_ BO_ 58 "raw ADC voltage reading of module3 cells 1-6";
 CM_ SG_ 58 "maximum cell temp from 25 to 30";
 CM_ SG_ 58 "minimum cell temp from 25 to 30";
 CM_ SG_ 58 "cell 30 temp";
 CM_ SG_ 58 "cell 29 temp";
 CM_ SG_ 58 "cell 28 temp";
 CM_ SG_ 58 "cell 27 temp";
 CM_ SG_ 58 "cell 26 temp";
 CM_ SG_ 58 "cell 25 temp";

CM_ BO_ 59 "raw ADC voltage reading of module3 cells 7-12";
 CM_ SG_ 59 "maximum cell temp from 31 to 36";
 CM_ SG_ 59 "minimum cell temp from 31 to 36";
 CM_ SG_ 59 "cell 36 temp";
 CM_ SG_ 59 "cell 35 temp";
 CM_ SG_ 59 "cell 34 temp";
 CM_ SG_ 59 "cell 33 temp";
 CM_ SG_ 59 "cell 32 temp";
 CM_ SG_ 59 "cell 31 temp";

CM_ BO_ 74 "raw ADC voltage reading of module4 cells 1-6";
 CM_ SG_ 74 "maximum cell temp from 37 to 42";
 CM_ SG_ 74 "minimum cell temp from 37 to 42";
 CM_ SG_ 74 "cell 42 temp";
 CM_ SG_ 74 "cell 41 temp";
 CM_ SG_ 74 "cell 40 temp";
 CM_ SG_ 74 "cell 39 temp";
 CM_ SG_ 74 "cell 38 temp";
 CM_ SG_ 74 "cell 37 temp";

CM_ BO_ 75 "raw ADC voltage reading of module4 cells 7-12";
 CM_ SG_ 75 "maximum cell temp from 43 to 48";
 CM_ SG_ 75 "minimum cell temp from 43 to 48";
 CM_ SG_ 75 "cell 48 temp";
 CM_ SG_ 75 "cell 47 temp";
 CM_ SG_ 75 "cell 46 temp";
 CM_ SG_ 75 "cell 45 temp";
 CM_ SG_ 75 "cell 44 temp";
 CM_ SG_ 75 "cell 43 temp";

CM_ BO_ 90 "raw ADC voltage reading of module5 cells 1-6";
 CM_ SG_ 90 "maximum cell temp from 49 to 54";
 CM_ SG_ 90 "minimum cell temp from 49 to 54";
 CM_ SG_ 90 "cell 54 temp";
 CM_ SG_ 90 "cell 53 temp";
 CM_ SG_ 90 "cell 52 temp";
 CM_ SG_ 90 "cell 51 temp";
 CM_ SG_ 90 "cell 50 temp";
 CM_ SG_ 90 "cell 49 temp";

CM_ BO_ 91 "raw ADC voltage reading of module5 cells 7-12";
 CM_ SG_ 91 "maximum cell temp from 55 to 60";
 CM_ SG_ 91 "minimum cell temp from 55 to 60";
 CM_ SG_ 91 "cell 60 temp";
 CM_ SG_ 91 "cell 59 temp";
 CM_ SG_ 91 "cell 58 temp";
 CM_ SG_ 91 "cell 57 temp";
 CM_ SG_ 91 "cell 56 temp";
 CM_ SG_ 91 "cell 55 temp";

CM_ BO_ 106 "raw ADC voltage reading of module6 cells 1-6";
 CM_ SG_ 106 "maximum cell temp from 61 to 66";
 CM_ SG_ 106 "minimum cell temp from 61 to 66";
 CM_ SG_ 106 "cell 66 temp";
 CM_ SG_ 106 "cell 65 temp";
 CM_ SG_ 106 "cell 64 temp";
 CM_ SG_ 106 "cell 63 temp";
 CM_ SG_ 106 "cell 62 temp";
 CM_ SG_ 106 "cell 61 temp";

CM_ BO_ 107 "raw ADC voltage reading of module6 cells 7-12";
 CM_ SG_ 107 "maximum cell temp from 67 to 72";
 CM_ SG_ 107 "minimum cell temp from 67 to 72";
 CM_ SG_ 107 "cell 72 temp";
 CM_ SG_ 107 "cell 71 temp";
 CM_ SG_ 107 "cell 70 temp";
 CM_ SG_ 107 "cell 69 temp";
 CM_ SG_ 107 "cell 68 temp";
 CM_ SG_ 107 "cell 67 temp";

BA_DEF_ SG_  "SystemSignalLongSymbol" STRING ;
BA_DEF_DEF_  "SystemSignalLongSymbol" "";
BA_ "SystemSignalLongSymbol" SG_ 469 D1_HV_Input_Current_Sensor_Valid "D1_HV_Input_Current_Sensor_Validity";
VAL_ 192 Inverter_Discharge 0 "Discharge Disable" 1 "Discharge Enable (if EEPROM parameter is set)" ;
VAL_ 192 Inverter_Enable 0 "Turn the inverter OFF" 1 "Turn the Inverter ON" ;
VAL_ 192 Direction_Command 0 "CW" 1 "CCW" ;
VAL_ 170 D2_Inverter_State 0 "Power up" 1 "Stop" 2 "Open Loop" 3 "Closed Loop" 4 "Internal State" 5 "Internal State" 6 "Internal State" 7 "Internal State" 8 "Idle Run" 9 "Idle Stop" 10 "Internal State" 11 "Intern State" 12 "Internal State" ;
VAL_ 170 D1_VSM_State 0 "VSM Start State" 1 "Pre-Charge Init state" 2 "pre-charge active state" 3 "pre-charge complete state" 4 "VSM wait state" 5 "VSM ready state" 6 "Motor Running State" 7 "blink fault code state" 14 "Shutdown state for Key Switch Mode 1" 15 "Reset the inverter" ;

BO_ 2364539904 EEC1 : 8 Vector__XXX
 SG_ Engine_Speed : 24|16@1+ (0.125,0) [0|8031.88] "rpm" Vector__XXX

CM_ BO_ 2364539904 "Engine Controller"
 CM_ SG_ 2364539904 Engine_Speed "A description for Engine speed."

BA_ "SingleFrame" BO_ 2364539904 0
